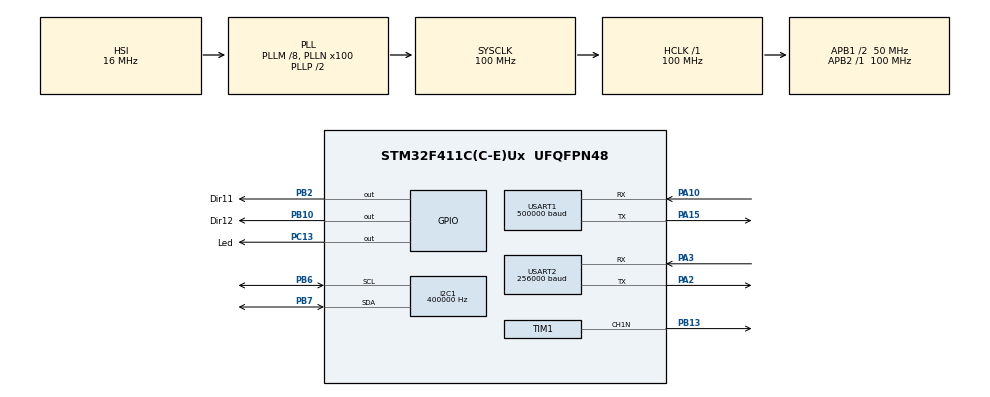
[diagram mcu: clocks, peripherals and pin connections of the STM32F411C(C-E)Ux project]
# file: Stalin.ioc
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I2C1.ClockSpeed=400000
I2C1.I2C_Mode=I2C_Fast
Mcu.Family=STM32F4
Mcu.Name=STM32F411C(C-E)Ux
Mcu.Package=UFQFPN48
NVIC.I2C1_ER_IRQn=true\:0\:0\:false\:false\:true\:true\:true\:true
NVIC.I2C1_EV_IRQn=true\:0\:0\:false\:false\:true\:true\:true\:true
NVIC.PriorityGroup=NVIC_PRIORITYGROUP_4
NVIC.USART1_IRQn=true\:0\:0\:false\:false\:true\:true\:true\:true
NVIC.USART2_IRQn=true\:0\:0\:false\:false\:true\:true\:true\:true
PA10.Mode=Asynchronous
PA10.Signal=USART1_RX
PA13.Mode=Serial_Wire
PA13.Signal=SYS_JTMS-SWDIO
PA14.Mode=Serial_Wire
PA14.Signal=SYS_JTCK-SWCLK
PA15.Mode=Asynchronous
PA15.Signal=USART1_TX
PA2.Mode=Asynchronous
PA2.Signal=USART2_TX
PA3.Mode=Asynchronous
PA3.Signal=USART2_RX
PB10.GPIO_Label=Dir12
PB10.Signal=GPIO_Output
PB13.Mode=PWM Generation1 CH1N
PB13.Signal=TIM1_CH1N
PB2.GPIO_Label=Dir11
PB2.Signal=GPIO_Output
PB6.GPIO_Pu=GPIO_NOPULL
PB6.Mode=I2C
PB6.Signal=I2C1_SCL
PB7.GPIO_Pu=GPIO_NOPULL
PB7.Mode=I2C
PB7.Signal=I2C1_SDA
PC13-ANTI_TAMP.GPIO_Label=Led
PC13-ANTI_TAMP.Signal=GPIO_Output
ProjectManager.HeapSize=0x2000
ProjectManager.StackSize=0x4000
ProjectManager.TargetToolchain=CMake
RCC.48MHZClocksFreq_Value=50000000
RCC.AHBFreq_Value=100000000
RCC.APB1CLKDivider=RCC_HCLK_DIV2
RCC.APB1Freq_Value=50000000
RCC.APB1TimFreq_Value=100000000
RCC.APB2Freq_Value=100000000
RCC.APB2TimFreq_Value=100000000
RCC.CortexFreq_Value=100000000
RCC.HCLKFreq_Value=100000000
RCC.HSE_VALUE=25000000
RCC.HSI_VALUE=16000000
RCC.LSE_VALUE=32768
RCC.PLLM=8
RCC.PLLN=100
RCC.SYSCLKFreq_VALUE=100000000
RCC.SYSCLKSource=RCC_SYSCLKSOURCE_PLLCLK
RCC.VCOOutputFreq_Value=200000000
TIM1.Channel-PWM\ Generation1\ CH1N=TIM_CHANNEL_1
TIM1.Period=5000
TIM1.Prescaler=16
USART1.BaudRate=500000
USART1.VirtualMode=VM_ASYNC
USART2.BaudRate=256000
USART2.VirtualMode=VM_ASYNC
board=custom

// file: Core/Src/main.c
/* USER CODE BEGIN Header */
/**
  ******************************************************************************
  * @file           : main.c
  * @brief          : Main program body
  ******************************************************************************
  * @attention
  *
  * Copyright (c) 2024 STMicroelectronics.
  * All rights reserved.
  *
  * This software is licensed under terms that can be found in the LICENSE file
  * in the root directory of this software component.
  * If no LICENSE file comes with this software, it is provided AS-IS.
  *
  ******************************************************************************
  */
/* USER CODE END Header */
#include "main.h"

/* USER CODE BEGIN Includes */
#include "App.h"
/* USER CODE END Includes */

I2C_HandleTypeDef hi2c1;

TIM_HandleTypeDef htim1;

UART_HandleTypeDef huart1;
UART_HandleTypeDef huart2;

void SystemClock_Config(void);
static void MX_GPIO_Init(void);
static void MX_TIM1_Init(void);
static void MX_USART1_UART_Init(void);
static void MX_USART2_UART_Init(void);
static void MX_I2C1_Init(void);

int main(void)
{

  /* MCU Configuration--------------------------------------------------------*/

  /* Reset of all peripherals, Initializes the Flash interface and the Systick. */
  HAL_Init();

  /* Configure the system clock */
  SystemClock_Config();

  /* Initialize all configured peripherals */
  MX_GPIO_Init();
  MX_TIM1_Init();
  MX_USART1_UART_Init();
  MX_USART2_UART_Init();
  MX_I2C1_Init();
  /* USER CODE BEGIN 2 */
  InitStartState();
  CrossCheck();
  App();
  /* USER CODE END 2 */

  /* Infinite loop */
  while (1)
  {

  }
}

void SystemClock_Config(void)
{
  RCC_OscInitTypeDef RCC_OscInitStruct = {0};
  RCC_ClkInitTypeDef RCC_ClkInitStruct = {0};

  /** Configure the main internal regulator output voltage
  */
  __HAL_RCC_PWR_CLK_ENABLE();
  __HAL_PWR_VOLTAGESCALING_CONFIG(PWR_REGULATOR_VOLTAGE_SCALE1);

  /** Initializes the RCC Oscillators according to the specified parameters
  * in the RCC_OscInitTypeDef structure.
  */
  RCC_OscInitStruct.OscillatorType = RCC_OSCILLATORTYPE_HSI;
  RCC_OscInitStruct.HSIState = RCC_HSI_ON;
  RCC_OscInitStruct.HSICalibrationValue = RCC_HSICALIBRATION_DEFAULT;
  RCC_OscInitStruct.PLL.PLLState = RCC_PLL_ON;
  RCC_OscInitStruct.PLL.PLLSource = RCC_PLLSOURCE_HSI;
  RCC_OscInitStruct.PLL.PLLM = 8;
  RCC_OscInitStruct.PLL.PLLN = 100;
  RCC_OscInitStruct.PLL.PLLP = RCC_PLLP_DIV2;
  RCC_OscInitStruct.PLL.PLLQ = 4;
  if (HAL_RCC_OscConfig(&RCC_OscInitStruct) != HAL_OK)
  {
    Error_Handler();
  }

  /** Initializes the CPU, AHB and APB buses clocks
  */
  RCC_ClkInitStruct.ClockType = RCC_CLOCKTYPE_HCLK|RCC_CLOCKTYPE_SYSCLK
                              |RCC_CLOCKTYPE_PCLK1|RCC_CLOCKTYPE_PCLK2;
  RCC_ClkInitStruct.SYSCLKSource = RCC_SYSCLKSOURCE_PLLCLK;
  RCC_ClkInitStruct.AHBCLKDivider = RCC_SYSCLK_DIV1;
  RCC_ClkInitStruct.APB1CLKDivider = RCC_HCLK_DIV2;
  RCC_ClkInitStruct.APB2CLKDivider = RCC_HCLK_DIV1;

  if (HAL_RCC_ClockConfig(&RCC_ClkInitStruct, FLASH_LATENCY_3) != HAL_OK)
  {
    Error_Handler();
  }
}

static void MX_I2C1_Init(void)
{

  hi2c1.Instance = I2C1;
  hi2c1.Init.ClockSpeed = 400000;
  hi2c1.Init.DutyCycle = I2C_DUTYCYCLE_2;
  hi2c1.Init.OwnAddress1 = 0;
  hi2c1.Init.AddressingMode = I2C_ADDRESSINGMODE_7BIT;
  hi2c1.Init.DualAddressMode = I2C_DUALADDRESS_DISABLE;
  hi2c1.Init.OwnAddress2 = 0;
  hi2c1.Init.GeneralCallMode = I2C_GENERALCALL_DISABLE;
  hi2c1.Init.NoStretchMode = I2C_NOSTRETCH_DISABLE;
  if (HAL_I2C_Init(&hi2c1) != HAL_OK)
  {
    Error_Handler();
  }

}

static void MX_TIM1_Init(void)
{

  TIM_MasterConfigTypeDef sMasterConfig = {0};
  TIM_OC_InitTypeDef sConfigOC = {0};
  TIM_BreakDeadTimeConfigTypeDef sBreakDeadTimeConfig = {0};

  htim1.Instance = TIM1;
  htim1.Init.Prescaler = 5;
  htim1.Init.CounterMode = TIM_COUNTERMODE_UP;
  htim1.Init.Period = 5000;
  htim1.Init.ClockDivision = TIM_CLOCKDIVISION_DIV1;
  htim1.Init.RepetitionCounter = 0;
  htim1.Init.AutoReloadPreload = TIM_AUTORELOAD_PRELOAD_DISABLE;
  if (HAL_TIM_PWM_Init(&htim1) != HAL_OK)
  {
    Error_Handler();
  }
  sMasterConfig.MasterOutputTrigger = TIM_TRGO_RESET;
  sMasterConfig.MasterSlaveMode = TIM_MASTERSLAVEMODE_DISABLE;
  if (HAL_TIMEx_MasterConfigSynchronization(&htim1, &sMasterConfig) != HAL_OK)
  {
    Error_Handler();
  }
  sConfigOC.OCMode = TIM_OCMODE_PWM1;
  sConfigOC.Pulse = 0;
  sConfigOC.OCPolarity = TIM_OCPOLARITY_HIGH;
  sConfigOC.OCNPolarity = TIM_OCNPOLARITY_HIGH;
  sConfigOC.OCFastMode = TIM_OCFAST_DISABLE;
  sConfigOC.OCIdleState = TIM_OCIDLESTATE_RESET;
  sConfigOC.OCNIdleState = TIM_OCNIDLESTATE_RESET;
  if (HAL_TIM_PWM_ConfigChannel(&htim1, &sConfigOC, TIM_CHANNEL_1) != HAL_OK)
  {
    Error_Handler();
  }
  sBreakDeadTimeConfig.OffStateRunMode = TIM_OSSR_DISABLE;
  sBreakDeadTimeConfig.OffStateIDLEMode = TIM_OSSI_DISABLE;
  sBreakDeadTimeConfig.LockLevel = TIM_LOCKLEVEL_OFF;
  sBreakDeadTimeConfig.DeadTime = 0;
  sBreakDeadTimeConfig.BreakState = TIM_BREAK_DISABLE;
  sBreakDeadTimeConfig.BreakPolarity = TIM_BREAKPOLARITY_HIGH;
  sBreakDeadTimeConfig.AutomaticOutput = TIM_AUTOMATICOUTPUT_DISABLE;
  if (HAL_TIMEx_ConfigBreakDeadTime(&htim1, &sBreakDeadTimeConfig) != HAL_OK)
  {
    Error_Handler();
  }
  HAL_TIM_MspPostInit(&htim1);

}

static void MX_USART1_UART_Init(void)
{

  huart1.Instance = USART1;
  huart1.Init.BaudRate = 500000;
  huart1.Init.WordLength = UART_WORDLENGTH_8B;
  huart1.Init.StopBits = UART_STOPBITS_1;
  huart1.Init.Parity = UART_PARITY_NONE;
  huart1.Init.Mode = UART_MODE_TX_RX;
  huart1.Init.HwFlowCtl = UART_HWCONTROL_NONE;
  huart1.Init.OverSampling = UART_OVERSAMPLING_16;
  if (HAL_UART_Init(&huart1) != HAL_OK)
  {
    Error_Handler();
  }

}

static void MX_USART2_UART_Init(void)
{

  huart2.Instance = USART2;
  huart2.Init.BaudRate = 256000;
  huart2.Init.WordLength = UART_WORDLENGTH_8B;
  huart2.Init.StopBits = UART_STOPBITS_1;
  huart2.Init.Parity = UART_PARITY_NONE;
  huart2.Init.Mode = UART_MODE_TX_RX;
  huart2.Init.HwFlowCtl = UART_HWCONTROL_NONE;
  huart2.Init.OverSampling = UART_OVERSAMPLING_16;
  if (HAL_UART_Init(&huart2) != HAL_OK)
  {
    Error_Handler();
  }

}

static void MX_GPIO_Init(void)
{
  GPIO_InitTypeDef GPIO_InitStruct = {0};

  /* GPIO Ports Clock Enable */
  __HAL_RCC_GPIOC_CLK_ENABLE();
  __HAL_RCC_GPIOA_CLK_ENABLE();
  __HAL_RCC_GPIOB_CLK_ENABLE();

  /*Configure GPIO pin Output Level */
  HAL_GPIO_WritePin(Led_GPIO_Port, Led_Pin, GPIO_PIN_RESET);

  /*Configure GPIO pin Output Level */
  HAL_GPIO_WritePin(GPIOB, Dir11_Pin|Dir12_Pin, GPIO_PIN_RESET);

  /*Configure GPIO pin : Led_Pin */
  GPIO_InitStruct.Pin = Led_Pin;
  GPIO_InitStruct.Mode = GPIO_MODE_OUTPUT_PP;
  GPIO_InitStruct.Pull = GPIO_NOPULL;
  GPIO_InitStruct.Speed = GPIO_SPEED_FREQ_LOW;
  HAL_GPIO_Init(Led_GPIO_Port, &GPIO_InitStruct);

  /*Configure GPIO pins : Dir11_Pin Dir12_Pin */
  GPIO_InitStruct.Pin = Dir11_Pin|Dir12_Pin;
  GPIO_InitStruct.Mode = GPIO_MODE_OUTPUT_PP;
  GPIO_InitStruct.Pull = GPIO_NOPULL;
  GPIO_InitStruct.Speed = GPIO_SPEED_FREQ_LOW;
  HAL_GPIO_Init(GPIOB, &GPIO_InitStruct);

}

void Error_Handler(void)
{
  __disable_irq();
  while (1)
  {
  }
}
